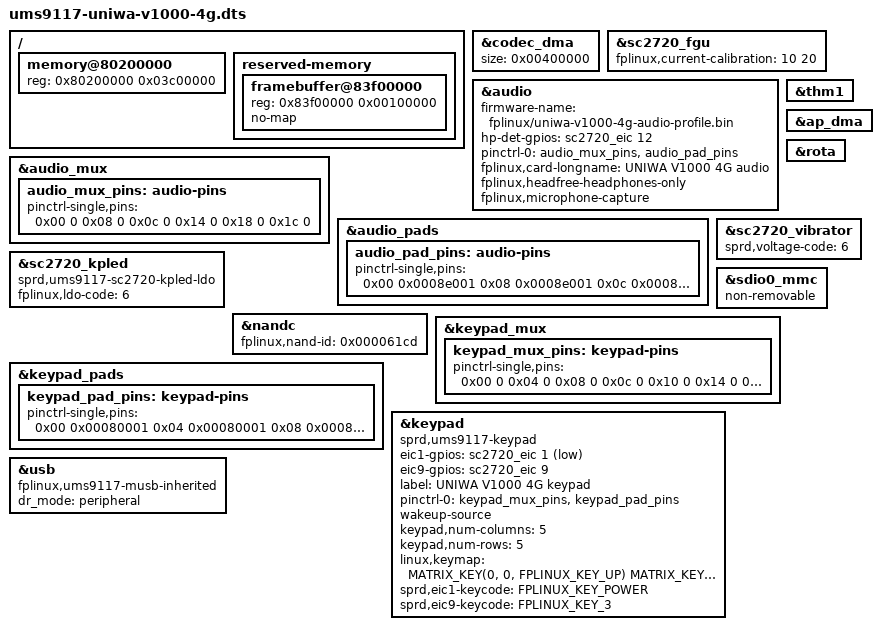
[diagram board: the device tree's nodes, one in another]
// SPDX-License-Identifier: GPL-2.0-only
/dts-v1/;

#include <dt-bindings/input/input.h>
#include <dt-bindings/input/fplinux-keypad.h>
#include <dt-bindings/gpio/gpio.h>
#include <dt-bindings/leds/common.h>
#include "ums9117.dtsi"
#include "ums9117-sc2720.dtsi"
#include "fplinux-uniwa-v1000-4g-identity.dtsi"
#include "ums9117-nand-readonly.dtsi"
#include "uniwa-v1000-4g-camera.dtsi"
#include "uniwa-v1000-4g-bluetooth.dtsi"
#include "uniwa-v1000-4g-display.dtsi"

/ {
	memory@80200000 {
		device_type = "memory";
		reg = <0x80200000 0x03c00000>;
	};

	reserved-memory {
		ranges;
		#address-cells = <1>;
		#size-cells = <1>;

		framebuffer@83f00000 {
			reg = <0x83f00000 0x00100000>;
			no-map;
		};
	};
};

#include "ums9117-ram-session.dtsi"

&codec_dma {
	size = <0x00400000>;
};

&sc2720_fgu {
	fplinux,current-calibration = <10 20>;
};

&audio {
	firmware-name = "fplinux/uniwa-v1000-4g-audio-profile.bin";
	hp-det-gpios = <&sc2720_eic 12 GPIO_ACTIVE_HIGH>;
	pinctrl-0 = <&audio_mux_pins &audio_pad_pins>;
	pinctrl-names = "audio";
	fplinux,card-longname = "UNIWA V1000 4G audio";
	fplinux,headfree-headphones-only;
	fplinux,microphone-capture;

	status = "okay";
};

&audio_mux {
	audio_mux_pins: audio-pins {
		pinctrl-single,pins = <
			0x00 0 0x08 0 0x0c 0 0x14 0 0x18 0 0x1c 0
		>;
	};
};

&audio_pads {
	audio_pad_pins: audio-pins {
		pinctrl-single,pins = <
			0x00 0x0008e001 0x08 0x0008e001 0x0c 0x0008e001
			0x14 0x0008e000 0x18 0x0008e000 0x1c 0x0008e001
		>;
	};
};

&thm1 {
	status = "okay";
};

&ap_dma {
	status = "okay";
};

&rota {
	status = "okay";
};

&sc2720_kpled {
	compatible = "sprd,ums9117-sc2720-kpled-ldo";
	fplinux,ldo-code = <6>;

	status = "okay";
};

&sc2720_vibrator {
	sprd,voltage-code = <6>;

	status = "okay";
};

&nandc {
	fplinux,nand-id = <0x000061cd>;
};

&sdio0_mmc {
	non-removable;

	status = "okay";
};

&keypad_mux {
	keypad_mux_pins: keypad-pins {
		pinctrl-single,pins = <
			0x00 0 0x04 0 0x08 0 0x0c 0 0x10 0
			0x14 0 0x18 0 0x1c 0 0x20 0 0x24 0
		>;
	};
};

&keypad_pads {
	keypad_pad_pins: keypad-pins {
		pinctrl-single,pins = <
			0x00 0x00080001 0x04 0x00080001 0x08 0x00080001
			0x0c 0x00080001 0x10 0x00080001 0x14 0x0008008a
			0x18 0x0008008a 0x1c 0x0008008a 0x20 0x0008008a
			0x24 0x0008008a
		>;
	};
};

&keypad {
	compatible = "sprd,ums9117-keypad";
	eic1-gpios = <&sc2720_eic 1 GPIO_ACTIVE_LOW>;
	eic9-gpios = <&sc2720_eic 9 GPIO_ACTIVE_HIGH>;
	label = "UNIWA V1000 4G keypad";
	pinctrl-0 = <&keypad_mux_pins &keypad_pad_pins>;
	pinctrl-names = "matrix";
	wakeup-source;
	keypad,num-columns = <5>;
	keypad,num-rows = <5>;
	linux,keymap = <
		MATRIX_KEY(0, 0, FPLINUX_KEY_UP)
		MATRIX_KEY(0, 1, FPLINUX_KEY_1)
		MATRIX_KEY(0, 2, FPLINUX_KEY_CALL)
		MATRIX_KEY(0, 3, FPLINUX_KEY_POUND)
		MATRIX_KEY(1, 0, FPLINUX_KEY_OK)
		MATRIX_KEY(1, 1, FPLINUX_KEY_STAR)
		MATRIX_KEY(1, 2, FPLINUX_KEY_2)
		MATRIX_KEY(1, 3, FPLINUX_KEY_DOWN)
		MATRIX_KEY(2, 0, FPLINUX_KEY_8)
		MATRIX_KEY(2, 1, FPLINUX_KEY_SOFT_RIGHT)
		MATRIX_KEY(2, 2, FPLINUX_KEY_6)
		MATRIX_KEY(2, 3, FPLINUX_KEY_4)
		MATRIX_KEY(3, 0, FPLINUX_KEY_7)
		MATRIX_KEY(3, 1, FPLINUX_KEY_0)
		MATRIX_KEY(3, 2, FPLINUX_KEY_5)
		MATRIX_KEY(3, 3, FPLINUX_KEY_9)
		MATRIX_KEY(4, 0, FPLINUX_KEY_LEFT)
		MATRIX_KEY(4, 1, FPLINUX_KEY_RIGHT)
		MATRIX_KEY(4, 2, FPLINUX_KEY_POUND)
		MATRIX_KEY(4, 3, FPLINUX_KEY_SOFT_LEFT)
	>;
	sprd,eic1-keycode = <FPLINUX_KEY_POWER>;
	sprd,eic9-keycode = <FPLINUX_KEY_3>;

	status = "okay";
};

&usb {
	compatible = "fplinux,ums9117-musb-inherited";
	dr_mode = "peripheral";

	status = "okay";
};
